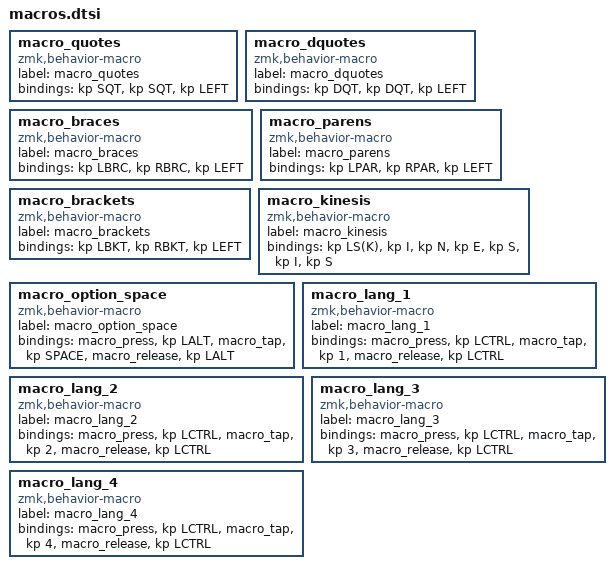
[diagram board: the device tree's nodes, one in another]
macro_quotes: macro_quotes{
compatible = "zmk,behavior-macro";
label = "macro_quotes";
#binding-cells = <0>;
bindings = <&kp SQT>, <&kp SQT>, <&kp LEFT>;
};
macro_dquotes: macro_dquotes{
compatible = "zmk,behavior-macro";
label = "macro_dquotes";
#binding-cells = <0>;
bindings = <&kp DQT>, <&kp DQT>, <&kp LEFT>;
};
macro_braces: macro_braces{
compatible = "zmk,behavior-macro";
label = "macro_braces";
#binding-cells = <0>;
bindings = <&kp LBRC>, <&kp RBRC>, <&kp LEFT>;
};
macro_parens: macro_parens{
compatible = "zmk,behavior-macro";
label = "macro_parens";
#binding-cells = <0>;
bindings = <&kp LPAR>, <&kp RPAR>, <&kp LEFT>;
};
macro_brackets: macro_brackets{
compatible = "zmk,behavior-macro";
label = "macro_brackets";
#binding-cells = <0>;
bindings = <&kp LBKT>, <&kp RBKT>, <&kp LEFT>;
};
macro_kinesis: macro_kinesis{
compatible = "zmk,behavior-macro";
label = "macro_kinesis";
#binding-cells = <0>;
bindings = <&kp LS(K)>, <&kp I>, <&kp N>, <&kp E>, <&kp S>, <&kp I>, <&kp S>;
};
macro_option_space: macro_option_space{
compatible = "zmk,behavior-macro";
label = "macro_option_space";
#binding-cells = <0>;
bindings = <&macro_press &kp LALT>, <&macro_tap &kp SPACE>, <&macro_release &kp LALT>;
};
macro_lang_1: macro_lang_1{
compatible = "zmk,behavior-macro";
label = "macro_lang_1";
#binding-cells = <0>;
bindings = <&macro_press &kp LCTRL>, <&macro_tap &kp 1>, <&macro_release &kp LCTRL>;
};
macro_lang_2: macro_lang_2{
compatible = "zmk,behavior-macro";
label = "macro_lang_2";
#binding-cells = <0>;
bindings = <&macro_press &kp LCTRL>, <&macro_tap &kp 2>, <&macro_release &kp LCTRL>;
};
macro_lang_3: macro_lang_3{
compatible = "zmk,behavior-macro";
label = "macro_lang_3";
#binding-cells = <0>;
bindings = <&macro_press &kp LCTRL>, <&macro_tap &kp 3>, <&macro_release &kp LCTRL>;
};
macro_lang_4: macro_lang_4{
compatible = "zmk,behavior-macro";
label = "macro_lang_4";
#binding-cells = <0>;
bindings = <&macro_press &kp LCTRL>, <&macro_tap &kp 4>, <&macro_release &kp LCTRL>;
};
